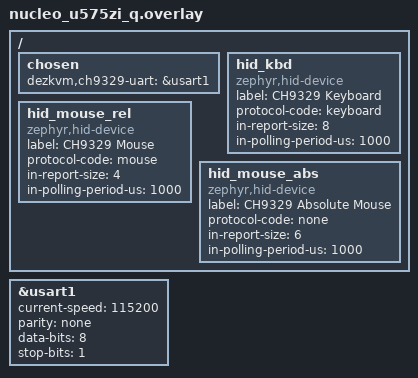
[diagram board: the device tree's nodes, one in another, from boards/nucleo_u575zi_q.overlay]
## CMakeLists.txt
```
cmake_minimum_required(VERSION 3.20.0)
find_package(Zephyr REQUIRED HINTS $ENV{ZEPHYR_BASE})
project(ch9329_stm32)

target_sources(app PRIVATE
	src/main.c
	src/ch9329_proto.c
	src/hid_out.c
	src/usb_dev.c
)
```

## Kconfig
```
# SPDX-License-Identifier: Apache-2.0

menu "CH9329 emulator"

config APP_USBD_VID
	hex "USB Vendor ID"
	default 0x046D
	help
	  Set this to the VID your existing firmware used.

config APP_USBD_PID
	hex "USB Product ID"
	default 0xC534
	help
	  Set this to the PID your existing firmware used.

config APP_USBD_MANUFACTURER
	string "USB manufacturer string"
	default "Logitech Inc."

config APP_USBD_PRODUCT
	string "USB product string"
	default "Nano Receiver"

config APP_USBD_REMOTE_WAKEUP
	bool "Advertise remote wakeup and wake a suspended host on keypress"
	default y

config APP_FRAME_TIMEOUT_MS
	int "Inter-byte silence (ms) after which a partial frame is discarded"
	default 10

endmenu

source "Kconfig.zephyr"
```

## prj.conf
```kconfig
CONFIG_CONSOLE=n
CONFIG_UART_CONSOLE=n
CONFIG_STDOUT_CONSOLE=n
CONFIG_EARLY_CONSOLE=n
CONFIG_SHELL=n
CONFIG_PRINTK=n
CONFIG_BOOT_BANNER=n
# Logging is off by default. Build with -DEXTRA_CONF_FILE=rtt.conf to get
# logs over SEGGER RTT instead (never UART) as this interferes with operation.
CONFIG_LOG=n

# Protocol UART 
CONFIG_SERIAL=y
CONFIG_UART_INTERRUPT_DRIVEN=y

# USB HID on OTG FS
CONFIG_USB_DEVICE_STACK_NEXT=y
CONFIG_USBD_HID_SUPPORT=y
```

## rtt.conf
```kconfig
CONFIG_LOG=y
CONFIG_LOG_MODE_DEFERRED=y
CONFIG_LOG_BACKEND_UART=n
CONFIG_USE_SEGGER_RTT=y
CONFIG_LOG_BACKEND_RTT=y
CONFIG_USBD_LOG_LEVEL_WRN=y
CONFIG_USBD_HID_LOG_LEVEL_WRN=y
CONFIG_UDC_DRIVER_LOG_LEVEL_WRN=y
```

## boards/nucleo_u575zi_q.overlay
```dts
/*
 * SPDX-License-Identifier: Apache-2.0
 *
 * USART1 (ST-Link VCP, PA9/PA10) is dedicated to the CH9329 protocol.
 * The board defaults route the console and shell to it; remove both so
 * nothing but protocol replies is ever transmitted on this UART.
 */

/ {
	chosen {
		/delete-property/ zephyr,console;
		/delete-property/ zephyr,shell-uart;
		dezkvm,ch9329-uart = &usart1;
	};
};

&usart1 {
	current-speed = <115200>;
	parity = "none";
	data-bits = <8>;
	stop-bits = "1";
	status = "okay";
};

/*
 * HID interfaces on OTG FS (CN15). Each node becomes its own USB interface.
 * in-report-size must match the report sizes in hid_out.c.
 */
/ {
	hid_kbd: hid_kbd {
		compatible = "zephyr,hid-device";
		label = "CH9329 Keyboard";
		protocol-code = "keyboard";
		in-report-size = <8>;
		in-polling-period-us = <1000>;
	};

	hid_mouse_rel: hid_mouse_rel {
		compatible = "zephyr,hid-device";
		label = "CH9329 Mouse";
		protocol-code = "mouse";
		in-report-size = <4>;
		in-polling-period-us = <1000>;
	};

	hid_mouse_abs: hid_mouse_abs {
		compatible = "zephyr,hid-device";
		label = "CH9329 Absolute Mouse";
		protocol-code = "none";
		in-report-size = <6>;
		in-polling-period-us = <1000>;
	};
};
```

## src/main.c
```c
/*
 * CH9329 emulator: CH9329 serial frames on USART1 (ST-Link VCP) are turned
 * into USB HID reports on OTG FS, so DezKVM-Go can drive this board as if it
 * were a CH340 + CH9329.
 */

#include <zephyr/device.h>
#include <zephyr/drivers/uart.h>
#include <zephyr/kernel.h>
#include <zephyr/logging/log.h>
#include <zephyr/sys/byteorder.h>
#include <zephyr/sys/ring_buffer.h>

#include "ch9329_proto.h"
#include "hid_out.h"
#include "usb_dev.h"

LOG_MODULE_REGISTER(main, LOG_LEVEL_INF);

static const struct device* const uart_dev =
    DEVICE_DT_GET(DT_CHOSEN(dezkvm_ch9329_uart));

RING_BUF_DECLARE(rx_ring, 256);
static K_SEM_DEFINE(rx_sem, 0, 1);
static struct k_spinlock rx_lock;

static struct ch9329_parser parser;

static void uart_isr(const struct device* dev, void* user_data) {
    uint8_t buf[16];
    int n;

    ARG_UNUSED(user_data);

    uart_irq_update(dev);

    while (uart_irq_rx_ready(dev)) {
        n = uart_fifo_read(dev, buf, sizeof(buf));
        if (n <= 0) {
            break;
        }
        /* On overflow the excess is dropped; the parser resyncs. */
        (void)ring_buf_put(&rx_ring, buf, n);
        k_sem_give(&rx_sem);
    }
}

static void reply_tx(const uint8_t* frame, size_t len, void* user_data) {
    ARG_UNUSED(user_data);

    /* 7 bytes at 115200 baud is ~0.6 ms; polling keeps this simple. */
    for (size_t i = 0; i < len; i++) {
        uart_poll_out(uart_dev, frame[i]);
    }
}

static uint8_t handle_cmd(uint8_t cmd, const uint8_t* data, uint8_t len,
                          void* user_data) {
    ARG_UNUSED(user_data);

    switch (cmd) {
        case CH9329_CMD_SEND_KB_GENERAL:
            /* [mod, 0x00, k1..k6] is already a boot keyboard report. */
            if (len != HID_KB_REPORT_LEN) {
                return CH9329_STATUS_ERR_PARA;
            }
            hid_out_keyboard(data);
            return CH9329_STATUS_SUCCESS;

        case CH9329_CMD_SEND_MS_ABS:
            /* [0x02, buttons, xL, xH, yL, yH, wheel] */
            if (len != 7 || data[0] != 0x02) {
                return CH9329_STATUS_ERR_PARA;
            }
            hid_out_mouse_abs(data[1], sys_get_le16(&data[2]),
                              sys_get_le16(&data[4]), (int8_t)data[6]);
            return CH9329_STATUS_SUCCESS;

        case CH9329_CMD_SEND_MS_REL:
            /* [0x01, buttons, dx, dy, wheel] */
            if (len != 5 || data[0] != 0x01) {
                return CH9329_STATUS_ERR_PARA;
            }
            hid_out_mouse_rel(data[1], (int8_t)data[2], (int8_t)data[3],
                              (int8_t)data[4]);
            return CH9329_STATUS_SUCCESS;

        case CH9329_CMD_RESET:
            hid_out_release_all();
            return CH9329_STATUS_SUCCESS;

        default:
            LOG_WRN("unsupported cmd 0x%02x len %u", cmd, len);
            return CH9329_STATUS_ERR_CMD;
    }
}

int main(void) {
    uint8_t buf[32];
    uint32_t n;
    int ret;

    if (!device_is_ready(uart_dev)) {
        LOG_ERR("CH9329 UART not ready");
        return -ENODEV;
    }

    ret = hid_out_init();
    if (ret != 0) {
        LOG_ERR("HID init failed, %d", ret);
        return ret;
    }

    ret = usb_dev_init();
    if (ret != 0) {
        LOG_ERR("USB init failed, %d", ret);
        return ret;
    }

    ch9329_parser_init(&parser, handle_cmd, reply_tx, NULL);

    ret = uart_irq_callback_user_data_set(uart_dev, uart_isr, NULL);
    if (ret != 0) {
        LOG_ERR("UART IRQ setup failed, %d", ret);
        return ret;
    }
    uart_irq_rx_enable(uart_dev);

    LOG_INF("CH9329 emulator ready");

    while (true) {
        k_timeout_t timeout = ch9329_parser_idle(&parser)
                                  ? K_FOREVER
                                  : K_MSEC(CONFIG_APP_FRAME_TIMEOUT_MS);

        if (k_sem_take(&rx_sem, timeout) != 0) {
            /* Inter-byte silence mid-frame: drop the partial frame. */
            LOG_DBG("frame timeout, resync");
            ch9329_parser_reset(&parser);
            continue;
        }

        do {
            K_SPINLOCK(&rx_lock) {
                n = ring_buf_get(&rx_ring, buf, sizeof(buf));
            }
            for (uint32_t i = 0; i < n; i++) {
                ch9329_parser_feed(&parser, buf[i]);
            }
        } while (n > 0);
    }

    return 0;
}
```

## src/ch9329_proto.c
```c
#include "ch9329_proto.h"

void ch9329_parser_init(struct ch9329_parser* p, ch9329_cmd_handler_t handler,
                        ch9329_reply_fn_t reply, void* user_data) {
    p->handler = handler;
    p->reply = reply;
    p->user_data = user_data;
    ch9329_parser_reset(p);
}

void ch9329_parser_reset(struct ch9329_parser* p) {
    p->state = CH9329_ST_HEAD0;
    p->cmd = 0;
    p->len = 0;
    p->idx = 0;
    p->sum = 0;
}

bool ch9329_parser_idle(const struct ch9329_parser* p) {
    return p->state == CH9329_ST_HEAD0;
}

size_t ch9329_build_reply(uint8_t cmd, uint8_t status,
                          uint8_t out[CH9329_REPLY_LEN]) {
    uint8_t sum = 0;

    out[0] = CH9329_HEAD0;
    out[1] = CH9329_HEAD1;
    out[2] = CH9329_ADDR;
    out[3] = cmd | (status == CH9329_STATUS_SUCCESS ? CH9329_REPLY_OK
                                                    : CH9329_REPLY_ERR);
    out[4] = 1;
    out[5] = status;

    for (int i = 0; i < CH9329_REPLY_LEN - 1; i++) {
        sum += out[i];
    }
    out[6] = sum;

    return CH9329_REPLY_LEN;
}

static void send_status(struct ch9329_parser* p, uint8_t status) {
    uint8_t frame[CH9329_REPLY_LEN];
    size_t len = ch9329_build_reply(p->cmd, status, frame);

    p->reply(frame, len, p->user_data);
}

/* Restart header scan; a stray 0x57 may itself begin the next frame. */
static void resync(struct ch9329_parser* p, uint8_t byte) {
    ch9329_parser_reset(p);
    if (byte == CH9329_HEAD0) {
        p->state = CH9329_ST_HEAD1;
        p->sum = byte;
    }
}

void ch9329_parser_feed(struct ch9329_parser* p, uint8_t byte) {
    switch (p->state) {
        case CH9329_ST_HEAD0:
            resync(p, byte);
            return;

        case CH9329_ST_HEAD1:
            if (byte != CH9329_HEAD1) {
                resync(p, byte);
                return;
            }
            p->state = CH9329_ST_ADDR;
            break;

        case CH9329_ST_ADDR:
            if (byte != CH9329_ADDR && byte != CH9329_ADDR_BCAST) {
                resync(p, byte);
                return;
            }
            p->state = CH9329_ST_CMD;
            break;

        case CH9329_ST_CMD:
            p->cmd = byte;
            p->state = CH9329_ST_LEN;
            break;

        case CH9329_ST_LEN:
            if (byte > CH9329_MAX_DATA) {
                /* Not a plausible frame; treat as line noise. */
                resync(p, byte);
                return;
            }
            p->len = byte;
            p->idx = 0;
            p->state = (byte == 0) ? CH9329_ST_SUM : CH9329_ST_DATA;
            break;

        case CH9329_ST_DATA:
            p->data[p->idx++] = byte;
            if (p->idx == p->len) {
                p->state = CH9329_ST_SUM;
            }
            break;

        case CH9329_ST_SUM: {
            uint8_t status;

            if (byte != p->sum) {
                status = CH9329_STATUS_ERR_SUM;
            } else {
                status = p->handler(p->cmd, p->data, p->len, p->user_data);
            }

            send_status(p, status);
            ch9329_parser_reset(p);
            return;
        }
    }

    p->sum += byte;
}
```

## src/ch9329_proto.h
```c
/*
 * WCH CH9329 serial protocol framing.
 *
 * Frame: 57 AB | addr | cmd | len | data[len] | sum
 * where sum = (sum of every preceding byte) & 0xFF.
 *
 * This file has no Zephyr dependencies so it can be unit-tested on a host.
 */

#ifndef CH9329_PROTO_H_
#define CH9329_PROTO_H_

#include <stdbool.h>
#include <stddef.h>
#include <stdint.h>

#define CH9329_HEAD0 0x57
#define CH9329_HEAD1 0xAB
#define CH9329_ADDR 0x00
#define CH9329_ADDR_BCAST 0xFF
#define CH9329_MAX_DATA 64
#define CH9329_REPLY_LEN 7

/* Commands */
#define CH9329_CMD_SEND_KB_GENERAL 0x02
#define CH9329_CMD_SEND_MS_ABS 0x04
#define CH9329_CMD_SEND_MS_REL 0x05
#define CH9329_CMD_RESET 0x0F

/* Reply cmd byte = cmd | REPLY_OK on success, cmd | REPLY_ERR on error */
#define CH9329_REPLY_OK 0x80
#define CH9329_REPLY_ERR 0xC0

/* Status codes carried in the 1-byte reply payload */
#define CH9329_STATUS_SUCCESS 0x00
#define CH9329_STATUS_ERR_TIMEOUT 0xE1
#define CH9329_STATUS_ERR_HEAD 0xE2
#define CH9329_STATUS_ERR_CMD 0xE3
#define CH9329_STATUS_ERR_SUM 0xE4
#define CH9329_STATUS_ERR_PARA 0xE5

/*
 * Called for every frame with a valid checksum. Returns the status code to
 * reply with. Must not block: replies are expected well within the host's
 * 300 ms timeout.
 */
typedef uint8_t (*ch9329_cmd_handler_t)(uint8_t cmd, const uint8_t* data,
                                        uint8_t len, void* user_data);

/* Called with a complete reply frame to transmit. */
typedef void (*ch9329_reply_fn_t)(const uint8_t* frame, size_t len,
                                  void* user_data);

enum ch9329_state {
    CH9329_ST_HEAD0,
    CH9329_ST_HEAD1,
    CH9329_ST_ADDR,
    CH9329_ST_CMD,
    CH9329_ST_LEN,
    CH9329_ST_DATA,
    CH9329_ST_SUM,
};

struct ch9329_parser {
    enum ch9329_state state;
    uint8_t cmd;
    uint8_t len;
    uint8_t idx;
    uint8_t sum;
    uint8_t data[CH9329_MAX_DATA];

    ch9329_cmd_handler_t handler;
    ch9329_reply_fn_t reply;
    void* user_data;
};

void ch9329_parser_init(struct ch9329_parser* p, ch9329_cmd_handler_t handler,
                        ch9329_reply_fn_t reply, void* user_data);

/* Discard any partial frame and start scanning for 57 AB again. */
void ch9329_parser_reset(struct ch9329_parser* p);

/* True when no partial frame is buffered. */
bool ch9329_parser_idle(const struct ch9329_parser* p);

void ch9329_parser_feed(struct ch9329_parser* p, uint8_t byte);

/* Build a 7-byte status reply for cmd. Returns the frame length. */
size_t ch9329_build_reply(uint8_t cmd, uint8_t status,
                          uint8_t out[CH9329_REPLY_LEN]);

#endif /* CH9329_PROTO_H_ */
```

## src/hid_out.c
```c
/*
 * USB HID report output.
 *
 * Each HID interface is a channel with a small FIFO of pending reports and
 * one transfer buffer. Callers never wait for USB: a report is queued and the
 * next one is submitted from the input_report_done() callback. Providing that
 * callback is what makes hid_device_submit_report() asynchronous; without it
 * the call blocks until the host polls, which could stall the UART replies.
 *
 * When the FIFO is full the oldest report is dropped, so the most recent
 * state (e.g. "all keys released") always reaches the host.
 */

#include "hid_out.h"

#include <string.h>
#include <zephyr/device.h>
#include <zephyr/kernel.h>
#include <zephyr/logging/log.h>
#include <zephyr/sys/byteorder.h>
#include <zephyr/usb/class/usbd_hid.h>
#include <zephyr/usb/usbd.h>

#include "usb_dev.h"

LOG_MODULE_REGISTER(hid_out, LOG_LEVEL_INF);

#define HID_MAX_REPORT_LEN 8
#define HID_QUEUE_LEN 8

struct hid_chan {
    const struct device* dev;
    const uint8_t* rdesc;
    uint16_t rdesc_len;
    uint8_t report_len;
    uint8_t* tx;

    struct k_spinlock lock;
    bool ready;
    bool busy;
    uint8_t head;
    uint8_t count;
    uint8_t queue[HID_QUEUE_LEN][HID_MAX_REPORT_LEN];
    /* Last report handed to USB, returned for Get_Report(Input). */
    uint8_t last[HID_MAX_REPORT_LEN];
};

/* Keyboard */

static const uint8_t kbd_rdesc[] = HID_KEYBOARD_REPORT_DESC();
UDC_STATIC_BUF_DEFINE(kbd_tx, HID_KB_REPORT_LEN);

/* Relative mouse: [buttons, dx, dy, wheel], boot-mouse compatible */

#define MOUSE_REL_REPORT_LEN 4

static const uint8_t mouse_rel_rdesc[] = HID_MOUSE_REPORT_DESC(3);
UDC_STATIC_BUF_DEFINE(mouse_rel_tx, MOUSE_REL_REPORT_LEN);

/* Absolute mouse: [buttons, xL, xH, yL, yH, wheel], X/Y 0..4095 */

#define MOUSE_ABS_REPORT_LEN 6
#define MOUSE_ABS_MAX 4095

static const uint8_t mouse_abs_rdesc[] = {
    HID_USAGE_PAGE(HID_USAGE_GEN_DESKTOP),
    HID_USAGE(HID_USAGE_GEN_DESKTOP_MOUSE),
    HID_COLLECTION(HID_COLLECTION_APPLICATION),
    HID_USAGE(HID_USAGE_GEN_DESKTOP_POINTER),
    HID_COLLECTION(HID_COLLECTION_PHYSICAL),
    /* 3 buttons + 5 bits padding */
    HID_USAGE_PAGE(HID_USAGE_GEN_BUTTON),
    HID_USAGE_MIN8(1),
    HID_USAGE_MAX8(3),
    HID_LOGICAL_MIN8(0),
    HID_LOGICAL_MAX8(1),
    HID_REPORT_SIZE(1),
    HID_REPORT_COUNT(3),
    /* HID_INPUT (Data,Var,Abs) */
    HID_INPUT(0x02),
    HID_REPORT_SIZE(5),
    HID_REPORT_COUNT(1),
    /* HID_INPUT (Cnst,Ary,Abs) */
    HID_INPUT(0x01),
    /* X, Y: uint16 0..4095 */
    HID_USAGE_PAGE(HID_USAGE_GEN_DESKTOP),
    HID_USAGE(HID_USAGE_GEN_DESKTOP_X),
    HID_USAGE(HID_USAGE_GEN_DESKTOP_Y),
    HID_LOGICAL_MIN8(0),
    HID_LOGICAL_MAX16(MOUSE_ABS_MAX & 0xFF, MOUSE_ABS_MAX >> 8),
    HID_REPORT_SIZE(16),
    HID_REPORT_COUNT(2),
    /* HID_INPUT (Data,Var,Abs) */
    HID_INPUT(0x02),
    /* Wheel: int8 */
    HID_USAGE(HID_USAGE_GEN_DESKTOP_WHEEL),
    HID_LOGICAL_MIN8(-127),
    HID_LOGICAL_MAX8(127),
    HID_REPORT_SIZE(8),
    HID_REPORT_COUNT(1),
    /* HID_INPUT (Data,Var,Rel) */
    HID_INPUT(0x06),
    HID_END_COLLECTION,
    HID_END_COLLECTION,
};
UDC_STATIC_BUF_DEFINE(mouse_abs_tx, MOUSE_ABS_REPORT_LEN);

enum {
    CHAN_KBD,
    CHAN_MOUSE_REL,
    CHAN_MOUSE_ABS,
    CHAN_COUNT,
};

static struct hid_chan chans[CHAN_COUNT] = {
    [CHAN_KBD] =
        {
            .dev = DEVICE_DT_GET(DT_NODELABEL(hid_kbd)),
            .rdesc = kbd_rdesc,
            .rdesc_len = sizeof(kbd_rdesc),
            .report_len = HID_KB_REPORT_LEN,
            .tx = kbd_tx,
        },
    [CHAN_MOUSE_REL] =
        {
            .dev = DEVICE_DT_GET(DT_NODELABEL(hid_mouse_rel)),
            .rdesc = mouse_rel_rdesc,
            .rdesc_len = sizeof(mouse_rel_rdesc),
            .report_len = MOUSE_REL_REPORT_LEN,
            .tx = mouse_rel_tx,
        },
    [CHAN_MOUSE_ABS] =
        {
            .dev = DEVICE_DT_GET(DT_NODELABEL(hid_mouse_abs)),
            .rdesc = mouse_abs_rdesc,
            .rdesc_len = sizeof(mouse_abs_rdesc),
            .report_len = MOUSE_ABS_REPORT_LEN,
            .tx = mouse_abs_tx,
        },
};

static struct hid_chan* chan_from_dev(const struct device* dev) {
    for (size_t i = 0; i < ARRAY_SIZE(chans); i++) {
        if (chans[i].dev == dev) {
            return &chans[i];
        }
    }

    return NULL;
}

/* Submit the next queued report if no transfer is in flight. */
static void chan_kick(struct hid_chan* ch) {
    k_spinlock_key_t key = k_spin_lock(&ch->lock);
    int ret;

    if (!ch->ready || ch->busy || ch->count == 0) {
        k_spin_unlock(&ch->lock, key);
        return;
    }

    memcpy(ch->tx, ch->queue[ch->head], ch->report_len);
    memcpy(ch->last, ch->tx, ch->report_len);
    ch->head = (ch->head + 1) % HID_QUEUE_LEN;
    ch->count--;
    ch->busy = true;
    k_spin_unlock(&ch->lock, key);

    ret = hid_device_submit_report(ch->dev, ch->report_len, ch->tx);
    if (ret != 0) {
        LOG_WRN("%s: submit failed (%d), flushing", ch->dev->name, ret);
        key = k_spin_lock(&ch->lock);
        ch->busy = false;
        ch->count = 0;
        k_spin_unlock(&ch->lock, key);
    }
}

static void chan_put(struct hid_chan* ch, const uint8_t* report) {
    k_spinlock_key_t key = k_spin_lock(&ch->lock);
    uint8_t tail;

    if (!ch->ready) {
        /* Not configured by the host: drop, the reply is still OK. */
        k_spin_unlock(&ch->lock, key);
        return;
    }

    if (ch->count == HID_QUEUE_LEN) {
        ch->head = (ch->head + 1) % HID_QUEUE_LEN;
        ch->count--;
    }

    tail = (ch->head + ch->count) % HID_QUEUE_LEN;
    memcpy(ch->queue[tail], report, ch->report_len);
    ch->count++;
    k_spin_unlock(&ch->lock, key);

    chan_kick(ch);
}

/* hid_device_ops (called from the USB stack thread, must not block) */

static void hid_iface_ready(const struct device* dev, const bool ready) {
    struct hid_chan* ch = chan_from_dev(dev);
    k_spinlock_key_t key;

    LOG_INF("%s %s", dev->name, ready ? "ready" : "not ready");

    key = k_spin_lock(&ch->lock);
    ch->ready = ready;
    ch->busy = false;
    ch->count = 0;
    k_spin_unlock(&ch->lock, key);
}

static void hid_input_report_done(const struct device* dev,
                                  const uint8_t* const report) {
    struct hid_chan* ch = chan_from_dev(dev);
    k_spinlock_key_t key = k_spin_lock(&ch->lock);

    ch->busy = false;
    k_spin_unlock(&ch->lock, key);

    chan_kick(ch);
}

static int hid_get_report(const struct device* dev, const uint8_t type,
                          const uint8_t id, const uint16_t len,
                          uint8_t* const buf) {
    struct hid_chan* ch = chan_from_dev(dev);
    uint16_t n = MIN(len, ch->report_len);

    if (type != HID_REPORT_TYPE_INPUT || id != 0) {
        return -ENOTSUP;
    }

    memcpy(buf, ch->last, n);

    return n;
}

static int hid_set_report(const struct device* dev, const uint8_t type,
                          const uint8_t id, const uint16_t len,
                          const uint8_t* const buf) {
    /* Keyboard LED output report: accepted and ignored. */
    if (type != HID_REPORT_TYPE_OUTPUT) {
        return -ENOTSUP;
    }

    return 0;
}

static void hid_set_idle(const struct device* dev, const uint8_t id,
                         const uint32_t duration) {
    /*
     * Must be present or the class stalls SET_IDLE, which strict
     * BIOS/UEFI boot-keyboard drivers treat as fatal. Reports are only
     * sent on change, so the requested rate is accepted and ignored.
     */
    LOG_DBG("%s: set idle id %u %u ms", dev->name, id, duration);
}

static void hid_set_protocol(const struct device* dev, const uint8_t proto) {
    /* Our report layouts are boot-compatible, nothing to switch. */
    LOG_INF("%s: %s protocol", dev->name, proto == 0U ? "boot" : "report");
}

static const struct hid_device_ops hid_ops = {
    .iface_ready = hid_iface_ready,
    .get_report = hid_get_report,
    .set_report = hid_set_report,
    .set_idle = hid_set_idle,
    .set_protocol = hid_set_protocol,
    .input_report_done = hid_input_report_done,
};

/* Public API */

int hid_out_init(void) {
    int ret;

    for (size_t i = 0; i < ARRAY_SIZE(chans); i++) {
        struct hid_chan* ch = &chans[i];

        if (!device_is_ready(ch->dev)) {
            LOG_ERR("%s not ready", ch->dev->name);
            return -ENODEV;
        }

        ret = hid_device_register(ch->dev, ch->rdesc, ch->rdesc_len, &hid_ops);
        if (ret != 0) {
            LOG_ERR("%s: register failed (%d)", ch->dev->name, ret);
            return ret;
        }
    }

    return 0;
}

void hid_out_keyboard(const uint8_t report[HID_KB_REPORT_LEN]) {
    if (usb_dev_is_suspended()) {
        usb_dev_wakeup();
    }

    chan_put(&chans[CHAN_KBD], report);
}

/* The descriptor's logical range is -127..127; -128 is not representable. */
static uint8_t clamp_rel(int8_t v) { return (uint8_t)MAX(v, -127); }

void hid_out_mouse_rel(uint8_t buttons, int8_t dx, int8_t dy, int8_t wheel) {
    uint8_t report[MOUSE_REL_REPORT_LEN] = {
        buttons & 0x07,
        clamp_rel(dx),
        clamp_rel(dy),
        clamp_rel(wheel),
    };

    chan_put(&chans[CHAN_MOUSE_REL], report);
}

/*
 * Last absolute position, so a reset can release buttons without moving the
 * pointer. Only touched from the protocol thread.
 */
static uint16_t abs_x;
static uint16_t abs_y;
static bool abs_used;

void hid_out_mouse_abs(uint8_t buttons, uint16_t x, uint16_t y, int8_t wheel) {
    uint8_t report[MOUSE_ABS_REPORT_LEN];

    x = MIN(x, MOUSE_ABS_MAX);
    y = MIN(y, MOUSE_ABS_MAX);
    abs_x = x;
    abs_y = y;
    abs_used = true;

    report[0] = buttons & 0x07;
    sys_put_le16(x, &report[1]);
    sys_put_le16(y, &report[3]);
    report[5] = clamp_rel(wheel);

    chan_put(&chans[CHAN_MOUSE_ABS], report);
}

void hid_out_release_all(void) {
    static const uint8_t zeros[HID_MAX_REPORT_LEN];

    chan_put(&chans[CHAN_KBD], zeros);
    chan_put(&chans[CHAN_MOUSE_REL], zeros);

    /* An all-zero absolute report would warp the pointer to (0, 0). */
    if (abs_used) {
        hid_out_mouse_abs(0, abs_x, abs_y, 0);
    }
}
```

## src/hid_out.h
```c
/*
 * USB HID report output. All functions are non-blocking: reports are queued
 * per interface and sent as the host polls. If an interface is not
 * configured by the host yet, the report is silently dropped.
 */

#ifndef HID_OUT_H_
#define HID_OUT_H_

#include <stdint.h>

#define HID_KB_REPORT_LEN 8

int hid_out_init(void);

/* Boot keyboard report: [modifiers, reserved, key1..key6]. */
void hid_out_keyboard(const uint8_t report[HID_KB_REPORT_LEN]);

void hid_out_mouse_rel(uint8_t buttons, int8_t dx, int8_t dy, int8_t wheel);

/* x, y in 0..4095 */
void hid_out_mouse_abs(uint8_t buttons, uint16_t x, uint16_t y, int8_t wheel);

/*
 * Release all keys and buttons. The absolute mouse keeps its last position
 * (an all-zero report would move the pointer to the top-left corner).
 */
void hid_out_release_all(void);

#endif /* HID_OUT_H_ */
```

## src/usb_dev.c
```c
/*
 * USB device context, descriptors and enable/VBUS handling.
 * The STM32U575 OTG_FS controller is full-speed only.
 */

#include "usb_dev.h"

#include <zephyr/device.h>
#include <zephyr/kernel.h>
#include <zephyr/logging/log.h>
#include <zephyr/usb/usbd.h>

LOG_MODULE_REGISTER(usb_dev, LOG_LEVEL_INF);

USBD_DEVICE_DEFINE(app_usbd, DEVICE_DT_GET(DT_NODELABEL(zephyr_udc0)),
                   CONFIG_APP_USBD_VID, CONFIG_APP_USBD_PID);

USBD_DESC_LANG_DEFINE(app_lang);
USBD_DESC_MANUFACTURER_DEFINE(app_mfr, CONFIG_APP_USBD_MANUFACTURER);
USBD_DESC_PRODUCT_DEFINE(app_product, CONFIG_APP_USBD_PRODUCT);
IF_ENABLED(CONFIG_HWINFO, (USBD_DESC_SERIAL_NUMBER_DEFINE(app_sn)));

USBD_DESC_CONFIG_DEFINE(fs_cfg_desc, "FS Configuration");

/* Powered from the ST-Link USB (CN1), not from the target on CN15. */
static const uint8_t attributes =
    USB_SCD_SELF_POWERED |
    (IS_ENABLED(CONFIG_APP_USBD_REMOTE_WAKEUP) ? USB_SCD_REMOTE_WAKEUP : 0);

USBD_CONFIGURATION_DEFINE(app_fs_config, attributes, 50, &fs_cfg_desc);

static void msg_cb(struct usbd_context* const usbd_ctx,
                   const struct usbd_msg* const msg) {
    LOG_INF("USBD message: %s", usbd_msg_type_string(msg->type));

    if (usbd_can_detect_vbus(usbd_ctx)) {
        if (msg->type == USBD_MSG_VBUS_READY) {
            if (usbd_enable(usbd_ctx)) {
                LOG_ERR("Failed to enable device support");
            }
        }

        if (msg->type == USBD_MSG_VBUS_REMOVED) {
            if (usbd_disable(usbd_ctx)) {
                LOG_ERR("Failed to disable device support");
            }
        }
    }
}

int usb_dev_init(void) {
    int err;

    err = usbd_add_descriptor(&app_usbd, &app_lang);
    if (err == 0) {
        err = usbd_add_descriptor(&app_usbd, &app_mfr);
    }
    if (err == 0) {
        err = usbd_add_descriptor(&app_usbd, &app_product);
    }
    IF_ENABLED(CONFIG_HWINFO, (if (err == 0) {
                   err = usbd_add_descriptor(&app_usbd, &app_sn);
               }))
    if (err) {
        LOG_ERR("Failed to add string descriptors (%d)", err);
        return err;
    }

    err = usbd_add_configuration(&app_usbd, USBD_SPEED_FS, &app_fs_config);
    if (err) {
        LOG_ERR("Failed to add configuration (%d)", err);
        return err;
    }

    err = usbd_register_all_classes(&app_usbd, USBD_SPEED_FS, 1, NULL);
    if (err) {
        LOG_ERR("Failed to register classes (%d)", err);
        return err;
    }

    /* Composite of plain HID interfaces: class info is per interface. */
    usbd_device_set_code_triple(&app_usbd, USBD_SPEED_FS, 0, 0, 0);
    usbd_self_powered(&app_usbd, true);

    err = usbd_msg_register_cb(&app_usbd, msg_cb);
    if (err) {
        LOG_ERR("Failed to register message callback (%d)", err);
        return err;
    }

    err = usbd_init(&app_usbd);
    if (err) {
        LOG_ERR("Failed to initialize device support (%d)", err);
        return err;
    }

    if (!usbd_can_detect_vbus(&app_usbd)) {
        err = usbd_enable(&app_usbd);
        if (err) {
            LOG_ERR("Failed to enable device support (%d)", err);
            return err;
        }
    }

    return 0;
}

bool usb_dev_is_suspended(void) { return usbd_is_suspended(&app_usbd); }

void usb_dev_wakeup(void) {
    int err;

    if (!IS_ENABLED(CONFIG_APP_USBD_REMOTE_WAKEUP)) {
        return;
    }

    err = usbd_wakeup_request(&app_usbd);
    if (err) {
        LOG_DBG("Remote wakeup not possible (%d)", err);
    }
}
```

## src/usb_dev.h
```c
#ifndef USB_DEV_H_
#define USB_DEV_H_

#include <stdbool.h>

/*
 * Set up descriptors and configuration, register all HID class instances
 * and enable the device (immediately, or on VBUS detection if supported).
 * HID devices must be registered with hid_device_register() first.
 */
int usb_dev_init(void);

/* True if the host has suspended the bus. */
bool usb_dev_is_suspended(void);

/* Request remote wakeup if the host allows it. */
void usb_dev_wakeup(void);

#endif /* USB_DEV_H_ */
```
